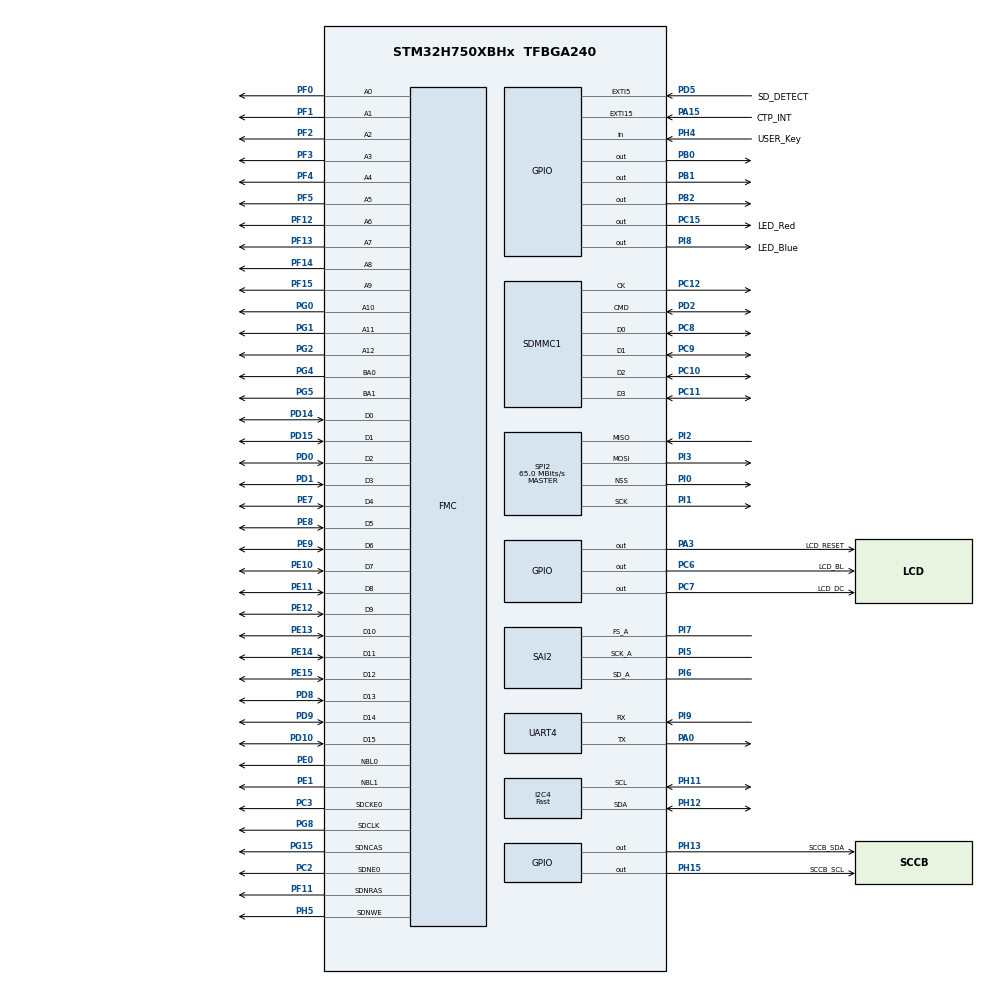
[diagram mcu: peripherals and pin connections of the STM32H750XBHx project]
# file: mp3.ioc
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DMA2D.ColorMode=DMA2D_OUTPUT_RGB888
DMA2D.InputColorModeForeground=DMA2D_INPUT_RGB565
DMA2D.Mode=DMA2D_M2M_PFC
DMA2D.RedBlueSwapForeground=DMA2D_RB_SWAP
Dma.Request0=SAI2_A
Dma.Request1=SPI2_TX
Dma.Request2=SPI2_RX
Dma.SAI2_A.0.Direction=DMA_MEMORY_TO_PERIPH
Dma.SAI2_A.0.EventEnable=DISABLE
Dma.SAI2_A.0.FIFOMode=DMA_FIFOMODE_DISABLE
Dma.SAI2_A.0.Instance=DMA1_Stream0
Dma.SAI2_A.0.MemDataAlignment=DMA_MDATAALIGN_WORD
Dma.SAI2_A.0.MemInc=DMA_MINC_ENABLE
Dma.SAI2_A.0.Mode=DMA_NORMAL
Dma.SAI2_A.0.PeriphDataAlignment=DMA_PDATAALIGN_WORD
Dma.SAI2_A.0.PeriphInc=DMA_PINC_DISABLE
Dma.SAI2_A.0.Polarity=HAL_DMAMUX_REQ_GEN_RISING
Dma.SAI2_A.0.Priority=DMA_PRIORITY_LOW
Dma.SAI2_A.0.RequestNumber=1
Dma.SAI2_A.0.SignalID=NONE
Dma.SAI2_A.0.SyncEnable=DISABLE
Dma.SAI2_A.0.SyncPolarity=HAL_DMAMUX_SYNC_NO_EVENT
Dma.SAI2_A.0.SyncRequestNumber=1
Dma.SAI2_A.0.SyncSignalID=NONE
Dma.SPI2_RX.2.Direction=DMA_PERIPH_TO_MEMORY
Dma.SPI2_RX.2.EventEnable=DISABLE
Dma.SPI2_RX.2.FIFOMode=DMA_FIFOMODE_ENABLE
Dma.SPI2_RX.2.FIFOThreshold=DMA_FIFO_THRESHOLD_FULL
Dma.SPI2_RX.2.Instance=DMA1_Stream2
Dma.SPI2_RX.2.MemBurst=DMA_MBURST_SINGLE
Dma.SPI2_RX.2.MemDataAlignment=DMA_MDATAALIGN_BYTE
Dma.SPI2_RX.2.MemInc=DMA_MINC_ENABLE
Dma.SPI2_RX.2.Mode=DMA_NORMAL
Dma.SPI2_RX.2.PeriphBurst=DMA_PBURST_SINGLE
Dma.SPI2_RX.2.PeriphDataAlignment=DMA_PDATAALIGN_BYTE
Dma.SPI2_RX.2.PeriphInc=DMA_PINC_DISABLE
Dma.SPI2_RX.2.Polarity=HAL_DMAMUX_REQ_GEN_RISING
Dma.SPI2_RX.2.Priority=DMA_PRIORITY_LOW
Dma.SPI2_RX.2.RequestNumber=1
Dma.SPI2_RX.2.SignalID=NONE
Dma.SPI2_RX.2.SyncEnable=DISABLE
Dma.SPI2_RX.2.SyncPolarity=HAL_DMAMUX_SYNC_NO_EVENT
Dma.SPI2_RX.2.SyncRequestNumber=1
Dma.SPI2_RX.2.SyncSignalID=NONE
Dma.SPI2_TX.1.Direction=DMA_MEMORY_TO_PERIPH
Dma.SPI2_TX.1.EventEnable=DISABLE
Dma.SPI2_TX.1.FIFOMode=DMA_FIFOMODE_ENABLE
Dma.SPI2_TX.1.FIFOThreshold=DMA_FIFO_THRESHOLD_FULL
Dma.SPI2_TX.1.Instance=DMA1_Stream1
Dma.SPI2_TX.1.MemBurst=DMA_MBURST_SINGLE
Dma.SPI2_TX.1.MemDataAlignment=DMA_MDATAALIGN_BYTE
Dma.SPI2_TX.1.MemInc=DMA_MINC_ENABLE
Dma.SPI2_TX.1.Mode=DMA_NORMAL
Dma.SPI2_TX.1.PeriphBurst=DMA_PBURST_SINGLE
Dma.SPI2_TX.1.PeriphDataAlignment=DMA_PDATAALIGN_BYTE
Dma.SPI2_TX.1.PeriphInc=DMA_PINC_DISABLE
Dma.SPI2_TX.1.Polarity=HAL_DMAMUX_REQ_GEN_RISING
Dma.SPI2_TX.1.Priority=DMA_PRIORITY_LOW
Dma.SPI2_TX.1.RequestNumber=1
Dma.SPI2_TX.1.SignalID=NONE
Dma.SPI2_TX.1.SyncEnable=DISABLE
Dma.SPI2_TX.1.SyncPolarity=HAL_DMAMUX_SYNC_NO_EVENT
Dma.SPI2_TX.1.SyncRequestNumber=1
Dma.SPI2_TX.1.SyncSignalID=NONE
FMC.CASLatency1=FMC_SDRAM_CAS_LATENCY_2
FMC.ColumnBitsNumber1=FMC_SDRAM_COLUMN_BITS_NUM_9
FMC.ExitSelfRefreshDelay1=1
FMC.LoadToActiveDelay1=2
FMC.RCDDelay1=1
FMC.RPDelay1=4
FMC.ReadPipeDelay1=FMC_SDRAM_RPIPE_DELAY_0
FMC.RowCycleDelay1=1
FMC.SDClockPeriod1=FMC_SDRAM_CLOCK_PERIOD_2
FMC.SDClockPeriod2=FMC_SDRAM_CLOCK_PERIOD_2
FMC.SelfRefreshTime1=1
FMC.WriteRecoveryTime1=2
I2C4.I2C_Speed_Mode=I2C_Fast
I2C4.Timing=0x00B03FDB
Mcu.Family=STM32H7
Mcu.Name=STM32H750XBHx
Mcu.Package=TFBGA240
NVIC.DMA1_Stream0_IRQn=true\:0\:0\:false\:false\:true\:false\:true
NVIC.DMA1_Stream1_IRQn=true\:0\:0\:false\:false\:true\:false\:true
NVIC.DMA1_Stream2_IRQn=true\:0\:0\:false\:false\:true\:false\:true
NVIC.DMA2D_IRQn=true\:0\:0\:false\:false\:true\:true\:true
NVIC.EXTI15_10_IRQn=true\:0\:0\:false\:false\:true\:true\:true
NVIC.EXTI9_5_IRQn=true\:5\:0\:true\:false\:true\:true\:true
NVIC.FMC_IRQn=true\:0\:0\:false\:false\:true\:true\:true
NVIC.PriorityGroup=NVIC_PRIORITYGROUP_4
NVIC.SDMMC1_IRQn=true\:6\:0\:true\:false\:true\:true\:true
NVIC.SPI2_IRQn=true\:0\:0\:false\:false\:true\:true\:true
NVIC.TIM2_IRQn=true\:0\:0\:false\:false\:true\:false\:true
NVIC.TimeBase=TIM2_IRQn
NVIC.TimeBaseIP=TIM2
NVIC.UART4_IRQn=true\:7\:0\:true\:false\:true\:true\:true
PA0.Mode=Asynchronous
PA0.Signal=UART4_TX
PA13\ (JTMS/SWDIO).Mode=Serial_Wire
PA13\ (JTMS/SWDIO).Signal=DEBUG_JTMS-SWDIO
PA14\ (JTCK/SWCLK).Mode=Serial_Wire
PA14\ (JTCK/SWCLK).PinAttribute=Free
PA14\ (JTCK/SWCLK).Signal=DEBUG_JTCK-SWCLK
PA15\ (JTDI).GPIO_Label=CTP_INT
PA15\ (JTDI).GPIO_ModeDefaultEXTI=GPIO_MODE_IT_FALLING
PA15\ (JTDI).PinAttribute=Free
PA15\ (JTDI).Signal=GPXTI15
PA3.GPIO_Label=LCD_RESET
PA3.Signal=GPIO_Output
PB0.Signal=GPIO_Output
PB1.Signal=GPIO_Output
PB2.Signal=GPIO_Output
PC10.Mode=SD_4_bits_Wide_bus
PC10.Signal=SDMMC1_D2
PC11.Mode=SD_4_bits_Wide_bus
PC11.PinAttribute=Free
PC11.Signal=SDMMC1_D3
PC12.Mode=SD_4_bits_Wide_bus
PC12.Signal=SDMMC1_CK
PC14-OSC32_IN\ (OSC32_IN).Mode=LSE-External-Clock-Source
PC14-OSC32_IN\ (OSC32_IN).Signal=RCC_OSC32_IN
PC15-OSC32_OUT\ (OSC32_OUT).GPIO_Label=LED_Red
PC15-OSC32_OUT\ (OSC32_OUT).PinState=GPIO_PIN_SET
PC15-OSC32_OUT\ (OSC32_OUT).Signal=GPIO_Output
PC2.Mode=SdramChipSelect1_1
PC2.Signal=FMC_SDNE0
PC3.Mode=SdramChipSelect1_1
PC3.Signal=FMC_SDCKE0
PC6.GPIO_Label=LCD_BL
PC6.Signal=GPIO_Output
PC7.GPIO_Label=LCD_DC
PC7.Signal=GPIO_Output
PC8.Mode=SD_4_bits_Wide_bus
PC8.PinAttribute=Free
PC8.Signal=SDMMC1_D0
PC9.Mode=SD_4_bits_Wide_bus
PC9.Signal=SDMMC1_D1
PD0.Signal=FMC_D2_DA2
PD1.PinAttribute=Free
PD1.Signal=FMC_D3_DA3
PD10.Signal=FMC_D15_DA15
PD14.Signal=FMC_D0_DA0
PD15.Signal=FMC_D1_DA1
PD2.Mode=SD_4_bits_Wide_bus
PD2.Signal=SDMMC1_CMD
PD5.GPIO_Label=SD_DETECT
PD5.GPIO_ModeDefaultEXTI=GPIO_MODE_IT_RISING_FALLING
PD5.Signal=GPXTI5
PD8.Signal=FMC_D13_DA13
PD9.Signal=FMC_D14_DA14
PE0.Signal=FMC_NBL0
PE1.PinAttribute=Free
PE1.Signal=FMC_NBL1
PE10.Signal=FMC_D7_DA7
PE11.Signal=FMC_D8_DA8
PE12.Signal=FMC_D9_DA9
PE13.Signal=FMC_D10_DA10
PE14.Signal=FMC_D11_DA11
PE15.Signal=FMC_D12_DA12
PE7.Signal=FMC_D4_DA4
PE8.Signal=FMC_D5_DA5
PE9.Signal=FMC_D6_DA6
PF0.Signal=FMC_A0
PF1.Signal=FMC_A1
PF11.Signal=FMC_SDNRAS
PF12.Signal=FMC_A6
PF13.Signal=FMC_A7
PF14.Signal=FMC_A8
PF15.Signal=FMC_A9
PF2.Signal=FMC_A2
PF3.Signal=FMC_A3
PF4.Signal=FMC_A4
PF5.Signal=FMC_A5
PG0.Signal=FMC_A10
PG1.Signal=FMC_A11
PG15.Signal=FMC_SDNCAS
PG2.Signal=FMC_A12
PG4.Signal=FMC_A14_BA0
PG5.Signal=FMC_A15_BA1
PG8.Signal=FMC_SDCLK
PH0-OSC_IN\ (PH0).Mode=HSE-External-Oscillator
PH0-OSC_IN\ (PH0).Signal=RCC_OSC_IN
PH1-OSC_OUT\ (PH1).Mode=HSE-External-Oscillator
PH1-OSC_OUT\ (PH1).Signal=RCC_OSC_OUT
PH11.Mode=I2C
PH11.Signal=I2C4_SCL
PH12.Mode=I2C
PH12.Signal=I2C4_SDA
PH13.GPIO_Label=SCCB_SDA
PH13.GPIO_Speed=GPIO_SPEED_FREQ_HIGH
PH13.PinAttribute=Free
PH13.PinState=GPIO_PIN_SET
PH13.Signal=GPIO_Output
PH15.GPIO_Label=SCCB_SCL
PH15.GPIO_Speed=GPIO_SPEED_FREQ_HIGH
PH15.PinState=GPIO_PIN_SET
PH15.Signal=GPIO_Output
PH4.GPIO_Label=USER_Key
PH4.Signal=GPIO_Input
PH5.Signal=FMC_SDNWE
PI0.GPIO_Speed=GPIO_SPEED_FREQ_VERY_HIGH
PI0.Mode=NSS_Signal_Hard_Output
PI0.Signal=SPI2_NSS
PI1.GPIO_Speed=GPIO_SPEED_FREQ_VERY_HIGH
PI1.Mode=Full_Duplex_Master
PI1.PinAttribute=Free
PI1.Signal=SPI2_SCK
PI2.GPIO_Speed=GPIO_SPEED_FREQ_VERY_HIGH
PI2.Mode=Full_Duplex_Master
PI2.PinAttribute=Free
PI2.Signal=SPI2_MISO
PI3.GPIO_Speed=GPIO_SPEED_FREQ_VERY_HIGH
PI3.Mode=Full_Duplex_Master
PI3.Signal=SPI2_MOSI
PI5.Mode=SAI_A_Master
PI5.Signal=SAI2_SCK_A
PI6.Mode=SAI_A_Master
PI6.Signal=SAI2_SD_A
PI7.Mode=SAI_A_Master
PI7.PinAttribute=Free
PI7.Signal=SAI2_FS_A
PI8.GPIO_Label=LED_Blue
PI8.PinAttribute=Free
PI8.PinState=GPIO_PIN_SET
PI8.Signal=GPIO_Output
PI9.Mode=Asynchronous
PI9.PinAttribute=Free
PI9.Signal=UART4_RX
ProjectManager.HeapSize=0x200
ProjectManager.StackSize=0x400
ProjectManager.TargetToolchain=Makefile
RCC.ADCFreq_Value=24000000
RCC.APB1Freq_Value=120000000
RCC.APB2Freq_Value=120000000
RCC.APB3Freq_Value=120000000
RCC.APB4Freq_Value=120000000
RCC.CortexFreq_Value=480000000
RCC.D1PPRE=RCC_APB3_DIV2
RCC.D2PPRE1=RCC_APB1_DIV2
RCC.D2PPRE2=RCC_APB2_DIV2
RCC.D3PPRE=RCC_APB4_DIV2
RCC.DIVM1=5
RCC.DIVM2=5
RCC.DIVM3=5
RCC.DIVN1=192
RCC.DIVN2=120
RCC.DIVN3=52
RCC.DIVP2=25
RCC.DIVQ1=8
RCC.DIVR2=6
RCC.FMCCLockSelection=RCC_FMCCLKSOURCE_PLL2
RCC.HCLKFreq_Value=240000000
RCC.HPRE=RCC_HCLK_DIV2
RCC.PLL1_VCO_SEL-AdvancedSettings=RCC_PLL1VCOMEDIUM
RCC.PLL2_VCO_SEL-AdvancedSettings=RCC_PLL2VCOMEDIUM
RCC.PLLSourceVirtual=RCC_PLLSOURCE_HSE
RCC.RTCClockSelection=RCC_RTCCLKSOURCE_LSE
RCC.SAI23CLockSelection=RCC_SAI23CLKSOURCE_PLL2
RCC.SDMMC1CLockSelection=RCC_SDMMCCLKSOURCE_PLL2
RCC.SPI123CLockSelection=RCC_SPI123CLKSOURCE_PLL3
RCC.SYSCLKFreq_VALUE=480000000
RCC.SYSCLKSource=RCC_SYSCLKSOURCE_PLLCLK
RCC.USBFreq_Value=120000000
SAI2.AudioFrequency-SAI_A_Master=SAI_AUDIO_FREQUENCY_48K
SAI2.ErrorAudioFreq-SAI_A_Master=-2.34 %
SAI2.InitProtocol-SAI_A_Master=Enable
SAI2.Instance-SAI_A_Master=SAI$Index_Block_A
SAI2.MClockEnable-SAI_A_Master=SAI_MASTERCLOCK_DISABLE
SAI2.NoDivider-SAI_A_Master=SAI_MASTERDIVIDER_DISABLE
SAI2.RealAudioFreq-SAI_A_Master=93.75 KHz
SAI2.VirtualMode-SAI_A_Master=VM_MASTER
SAI2.VirtualProtocol-SAI_A_BASIC=VM_BASIC_PROTOCOL
SH.FMC_A0.0=FMC_A0,13b-sda1
SH.FMC_A1.0=FMC_A1,13b-sda1
SH.FMC_A10.0=FMC_A10,13b-sda1
SH.FMC_A11.0=FMC_A11,13b-sda1
SH.FMC_A12.0=FMC_A12,13b-sda1
SH.FMC_A14_BA0.0=FMC_BA0,FourSdramBanks1
SH.FMC_A15_BA1.0=FMC_BA1,FourSdramBanks1
SH.FMC_A2.0=FMC_A2,13b-sda1
SH.FMC_A3.0=FMC_A3,13b-sda1
SH.FMC_A4.0=FMC_A4,13b-sda1
SH.FMC_A5.0=FMC_A5,13b-sda1
SH.FMC_A6.0=FMC_A6,13b-sda1
SH.FMC_A7.0=FMC_A7,13b-sda1
SH.FMC_A8.0=FMC_A8,13b-sda1
SH.FMC_A9.0=FMC_A9,13b-sda1
SH.FMC_D0_DA0.0=FMC_D0,sd-16b-d1
SH.FMC_D10_DA10.0=FMC_D10,sd-16b-d1
SH.FMC_D11_DA11.0=FMC_D11,sd-16b-d1
SH.FMC_D12_DA12.0=FMC_D12,sd-16b-d1
SH.FMC_D13_DA13.0=FMC_D13,sd-16b-d1
SH.FMC_D14_DA14.0=FMC_D14,sd-16b-d1
SH.FMC_D15_DA15.0=FMC_D15,sd-16b-d1
SH.FMC_D1_DA1.0=FMC_D1,sd-16b-d1
SH.FMC_D2_DA2.0=FMC_D2,sd-16b-d1
SH.FMC_D3_DA3.0=FMC_D3,sd-16b-d1
SH.FMC_D4_DA4.0=FMC_D4,sd-16b-d1
SH.FMC_D5_DA5.0=FMC_D5,sd-16b-d1
SH.FMC_D6_DA6.0=FMC_D6,sd-16b-d1
SH.FMC_D7_DA7.0=FMC_D7,sd-16b-d1
SH.FMC_D8_DA8.0=FMC_D8,sd-16b-d1
SH.FMC_D9_DA9.0=FMC_D9,sd-16b-d1
SH.FMC_NBL0.0=FMC_NBL0,Sd2ByteEnable1
SH.FMC_NBL1.0=FMC_NBL1,Sd2ByteEnable1
SH.FMC_SDCLK.0=FMC_SDCLK,13b-sda1
SH.FMC_SDNCAS.0=FMC_SDNCAS,13b-sda1
SH.FMC_SDNRAS.0=FMC_SDNRAS,13b-sda1
SH.FMC_SDNWE.0=FMC_SDNWE,13b-sda1
SPI2.BaudRatePrescaler=SPI_BAUDRATEPRESCALER_2
SPI2.CLKPhase=SPI_PHASE_2EDGE
SPI2.CLKPolarity=SPI_POLARITY_HIGH
SPI2.CalculateBaudRate=65.0 MBits/s
SPI2.DataSize=SPI_DATASIZE_8BIT
SPI2.Direction=SPI_DIRECTION_2LINES
SPI2.FifoThreshold=SPI_FIFO_THRESHOLD_16DATA
SPI2.MasterKeepIOState=SPI_MASTER_KEEP_IO_STATE_ENABLE
SPI2.MasterSSIdleness=SPI_MASTER_SS_IDLENESS_00CYCLE
SPI2.Mode=SPI_MODE_MASTER
SPI2.RxCRCInitializationPattern=SPI_CRC_INITIALIZATION_ALL_ONE_PATTERN
SPI2.TxCRCInitializationPattern=SPI_CRC_INITIALIZATION_ALL_ONE_PATTERN
SPI2.VirtualNSS=VM_NSSHARD
SPI2.VirtualType=VM_MASTER
UART4.FIFOMode=FIFOMODE_DISABLE
UART4.RXFIFOThreshold=RXFIFO_THRESHOLD_FULL
UART4.TXFIFOThreshold=TXFIFO_THRESHOLD_EMPTY
VP_DMA2D_VS_DMA2D.Mode=DMA2D_Activate
VP_RTC_VS_RTC_Activate.Mode=RTC_Enabled
VP_SAI2_VP_$IpInstance_SAIA_SAI_BASIC.Mode=SAI_A_BASIC
VP_SYS_VS_tim2.Mode=TIM2
board=custom

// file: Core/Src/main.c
/* USER CODE BEGIN Header */
/**
  ******************************************************************************
  * @file           : main.c
  * @brief          : Main program body
  ******************************************************************************
  * @attention
  *
  * <h2><center>&copy; Copyright (c) 2021 STMicroelectronics.
  * All rights reserved.</center></h2>
  *
  * This software component is licensed by ST under BSD 3-Clause license,
  * the "License"; You may not use this file except in compliance with the
  * License. You may obtain a copy of the License at:
  *                        opensource.org/licenses/BSD-3-Clause
  *
  ******************************************************************************
  */
/* USER CODE END Header */
#include "main.h"
#include "dma.h"
#include "dma2d.h"
#include "i2c.h"
#include "rtc.h"
#include "sai.h"
#include "sdmmc.h"
#include "spi.h"
#include "usart.h"
#include "gpio.h"
#include "fmc.h"

/* USER CODE BEGIN Includes */
#include "sdram.h"

#include "app_main.h"

/* USER CODE END Includes */

void SystemClock_Config(void);
void PeriphCommonClock_Config(void);

int main(void)
{

  /* MCU Configuration--------------------------------------------------------*/

  /* Reset of all peripherals, Initializes the Flash interface and the Systick. */
  HAL_Init();

  /* Configure the system clock */
  SystemClock_Config();

/* Configure the peripherals common clocks */
  PeriphCommonClock_Config();

  /* Initialize all configured peripherals */
  MX_GPIO_Init();
  MX_DMA_Init();
  MX_UART4_Init();
  MX_RTC_Init();
  MX_I2C4_Init();
  MX_SAI2_Init();
  MX_SDMMC1_SD_Init();
  MX_SPI2_Init();
  MX_FMC_Init();
  MX_DMA2D_Init();
  /* USER CODE BEGIN 2 */
  SDRAM_Init(); //Init SDRAM before anyother application start.

  app_main();//All apps start here.

  /* USER CODE END 2 */

  /* Infinite loop */
  while (1)
  {

  }
}

void SystemClock_Config(void)
{
  RCC_OscInitTypeDef RCC_OscInitStruct = {0};
  RCC_ClkInitTypeDef RCC_ClkInitStruct = {0};

  /** Supply configuration update enable
  */
  HAL_PWREx_ConfigSupply(PWR_LDO_SUPPLY);
  /** Configure the main internal regulator output voltage
  */
  __HAL_PWR_VOLTAGESCALING_CONFIG(PWR_REGULATOR_VOLTAGE_SCALE0);

  while(!__HAL_PWR_GET_FLAG(PWR_FLAG_VOSRDY)) {}
  /** Macro to configure the PLL clock source
  */
  __HAL_RCC_PLL_PLLSOURCE_CONFIG(RCC_PLLSOURCE_HSE);
  /** Initializes the RCC Oscillators according to the specified parameters
  * in the RCC_OscInitTypeDef structure.
  */
  RCC_OscInitStruct.OscillatorType = RCC_OSCILLATORTYPE_HSE|RCC_OSCILLATORTYPE_LSE;
  RCC_OscInitStruct.HSEState = RCC_HSE_ON;
  RCC_OscInitStruct.LSEState = RCC_LSE_BYPASS;
  RCC_OscInitStruct.PLL.PLLState = RCC_PLL_ON;
  RCC_OscInitStruct.PLL.PLLSource = RCC_PLLSOURCE_HSE;
  RCC_OscInitStruct.PLL.PLLM = 5;
  RCC_OscInitStruct.PLL.PLLN = 192;
  RCC_OscInitStruct.PLL.PLLP = 2;
  RCC_OscInitStruct.PLL.PLLQ = 8;
  RCC_OscInitStruct.PLL.PLLR = 2;
  RCC_OscInitStruct.PLL.PLLRGE = RCC_PLL1VCIRANGE_2;
  RCC_OscInitStruct.PLL.PLLVCOSEL = RCC_PLL1VCOWIDE;
  RCC_OscInitStruct.PLL.PLLFRACN = 0;
  if (HAL_RCC_OscConfig(&RCC_OscInitStruct) != HAL_OK)
  {
    Error_Handler();
  }
  /** Initializes the CPU, AHB and APB buses clocks
  */
  RCC_ClkInitStruct.ClockType = RCC_CLOCKTYPE_HCLK|RCC_CLOCKTYPE_SYSCLK
                              |RCC_CLOCKTYPE_PCLK1|RCC_CLOCKTYPE_PCLK2
                              |RCC_CLOCKTYPE_D3PCLK1|RCC_CLOCKTYPE_D1PCLK1;
  RCC_ClkInitStruct.SYSCLKSource = RCC_SYSCLKSOURCE_PLLCLK;
  RCC_ClkInitStruct.SYSCLKDivider = RCC_SYSCLK_DIV1;
  RCC_ClkInitStruct.AHBCLKDivider = RCC_HCLK_DIV2;
  RCC_ClkInitStruct.APB3CLKDivider = RCC_APB3_DIV2;
  RCC_ClkInitStruct.APB1CLKDivider = RCC_APB1_DIV2;
  RCC_ClkInitStruct.APB2CLKDivider = RCC_APB2_DIV2;
  RCC_ClkInitStruct.APB4CLKDivider = RCC_APB4_DIV2;

  if (HAL_RCC_ClockConfig(&RCC_ClkInitStruct, FLASH_LATENCY_4) != HAL_OK)
  {
    Error_Handler();
  }
}

void PeriphCommonClock_Config(void)
{
  RCC_PeriphCLKInitTypeDef PeriphClkInitStruct = {0};

  /** Initializes the peripherals clock
  */
  PeriphClkInitStruct.PeriphClockSelection = RCC_PERIPHCLK_FMC|RCC_PERIPHCLK_SDMMC
                              |RCC_PERIPHCLK_SAI2;
  PeriphClkInitStruct.PLL2.PLL2M = 5;
  PeriphClkInitStruct.PLL2.PLL2N = 120;
  PeriphClkInitStruct.PLL2.PLL2P = 25;
  PeriphClkInitStruct.PLL2.PLL2Q = 2;
  PeriphClkInitStruct.PLL2.PLL2R = 6;
  PeriphClkInitStruct.PLL2.PLL2RGE = RCC_PLL2VCIRANGE_2;
  PeriphClkInitStruct.PLL2.PLL2VCOSEL = RCC_PLL2VCOWIDE;
  PeriphClkInitStruct.PLL2.PLL2FRACN = 0;
  PeriphClkInitStruct.FmcClockSelection = RCC_FMCCLKSOURCE_PLL2;
  PeriphClkInitStruct.SdmmcClockSelection = RCC_SDMMCCLKSOURCE_PLL2;
  PeriphClkInitStruct.Sai23ClockSelection = RCC_SAI23CLKSOURCE_PLL2;
  if (HAL_RCCEx_PeriphCLKConfig(&PeriphClkInitStruct) != HAL_OK)
  {
    Error_Handler();
  }
}

 /**
  * @brief  Period elapsed callback in non blocking mode
  * @note   This function is called  when TIM2 interrupt took place, inside
  * HAL_TIM_IRQHandler(). It makes a direct call to HAL_IncTick() to increment
  * a global variable "uwTick" used as application time base.
  * @param  htim : TIM handle
  * @retval None
  */
void HAL_TIM_PeriodElapsedCallback(TIM_HandleTypeDef *htim)
{
  if (htim->Instance == TIM2) {
    HAL_IncTick();
  }
}

void Error_Handler(void)
{
  __disable_irq();
  while (1)
  {
  }
}

/************************ (C) COPYRIGHT STMicroelectronics *****END OF FILE****/
